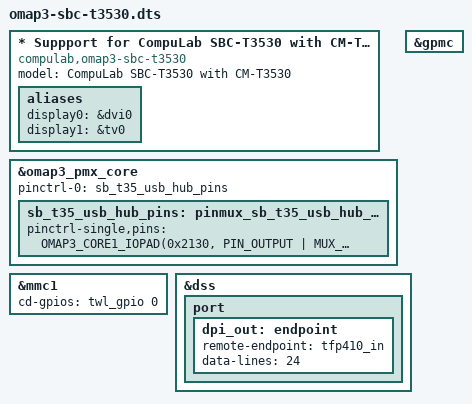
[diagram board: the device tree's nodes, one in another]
/* bench 11690.1.0 01d5a91cc080 */
/* bench 11690.1.1 fceda60d4f16 */
/* bench 11690.1.2 42b7ea78bf8c */
/* bench 11690.1.3 063d088e3f0c */
/* bench 11690.1.4 0cfb638d2f82 */
/* bench 11690.1.5 8d37cd6e4629 */
/* bench 11690.1.6 6fa81176180b */
/* bench 11690.1.7 8873f241556f */
/* bench 11690.1.8 c8d6ef4cd024 */
/* bench 11690.1.9 4d229bd38832 */
/* bench 11690.1.10 5ff881f633a0 */
/* bench 11690.1.11 9c3f2f3a1ad1 */
 * Suppport for CompuLab SBC-T3530 with CM-T3530
 */

#include "omap3-cm-t3530.dts"
#include "omap3-sb-t35.dtsi"

/ {
	model = "CompuLab SBC-T3530 with CM-T3530";
	compatible = "compulab,omap3-sbc-t3530", "compulab,omap3-cm-t3530", "ti,omap3430", "ti,omap34xx", "ti,omap3";

	aliases {
		display0 = &dvi0;
		display1 = &tv0;
	};
};

&omap3_pmx_core {
	pinctrl-names = "default";
	pinctrl-0 = <&sb_t35_usb_hub_pins>;

	sb_t35_usb_hub_pins: pinmux_sb_t35_usb_hub_pins {
		pinctrl-single,pins = <
			OMAP3_CORE1_IOPAD(0x2130, PIN_OUTPUT | MUX_MODE4) /* ccdc_wen.gpio_167 - SB-T35 USB HUB RST */
		>;
	};
};

&gpmc {
	ranges = <5 0 0x2c000000 0x01000000>,	/* CM-T3x30 SMSC9x Eth */
		 <4 0 0x2d000000 0x01000000>,	/* SB-T35 SMSC9x Eth */
		 <0 0 0x00000000 0x01000000>;	/* CM-T3x NAND */
};

&mmc1 {
	cd-gpios =  <&twl_gpio 0 GPIO_ACTIVE_HIGH>;
};

&dss {
	port {
		dpi_out: endpoint {
			remote-endpoint = <&tfp410_in>;
			data-lines = <24>;
		};
	};
};

